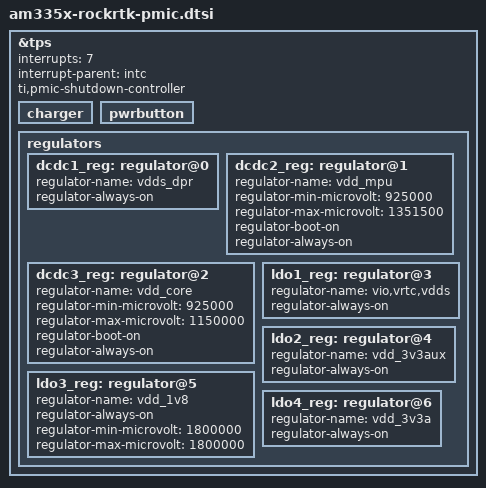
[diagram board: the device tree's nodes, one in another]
/include/ "../../tps65217.dtsi"

&tps {
	/*
	 * Configure pmic to enter OFF-state instead of SLEEP-state ("RTC-only
	 * mode") at poweroff.  Most BeagleBone versions do not support RTC-only
	 * mode and risk hardware damage if this mode is entered.
	 *
	 * For details, see linux-omap mailing list May 2015 thread
	 *	[PATCH] ARM: dts: am335x-bone* enable pmic-shutdown-controller
	 * In particular, messages:
	 *	https://www.spinics.net/lists/linux-omap/msg118585.html
	 *	https://www.spinics.net/lists/linux-omap/msg118615.html
	 *
	 * You can override this later with
	 *	&tps {  /delete-property/ ti,pmic-shutdown-controller;  }
	 * if you want to use RTC-only mode and made sure you are not affected
	 * by the hardware problems. (Tip: double-check by performing a current
	 * measurement after shutdown: it should be less than 1 mA.)
	 */

	interrupts = <7>; /* NMI */
	interrupt-parent = <&intc>;

	ti,pmic-shutdown-controller;

	charger {
		status = "okay";
	};

	pwrbutton {
		status = "okay";
	};

	regulators {
		dcdc1_reg: regulator@0 {
			regulator-name = "vdds_dpr";
			regulator-always-on;
		};

		dcdc2_reg: regulator@1 {
			/* VDD_MPU voltage limits 0.95V - 1.26V with +/-4% tolerance */
			regulator-name = "vdd_mpu";
			regulator-min-microvolt = <925000>;
			regulator-max-microvolt = <1351500>;
			regulator-boot-on;
			regulator-always-on;
		};

		dcdc3_reg: regulator@2 {
			/* VDD_CORE voltage limits 0.95V - 1.1V with +/-4% tolerance */
			regulator-name = "vdd_core";
			regulator-min-microvolt = <925000>;
			regulator-max-microvolt = <1150000>;
			regulator-boot-on;
			regulator-always-on;
		};

		ldo1_reg: regulator@3 {
			regulator-name = "vio,vrtc,vdds";
			regulator-always-on;
		};

		ldo2_reg: regulator@4 {
			regulator-name = "vdd_3v3aux";
			regulator-always-on;
		};

		ldo3_reg: regulator@5 {
			regulator-name = "vdd_1v8";
			regulator-always-on;
            regulator-min-microvolt = <1800000>;
            regulator-max-microvolt = <1800000>;
		};

		ldo4_reg: regulator@6 {
			regulator-name = "vdd_3v3a";
			regulator-always-on;
		};
	};
};
